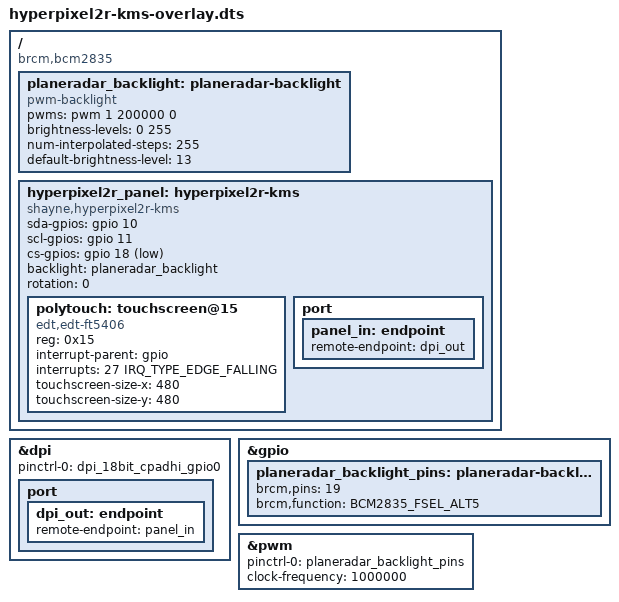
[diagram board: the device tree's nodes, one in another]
// SPDX-License-Identifier: GPL-2.0-only
#include <dt-bindings/gpio/gpio.h>
#include <dt-bindings/interrupt-controller/irq.h>
#include <dt-bindings/pinctrl/bcm2835.h>

/dts-v1/;
/plugin/;

/ {
	compatible = "brcm,bcm2835";

	fragment@0 {
		target-path = "/";
		__overlay__ {
			planeradar_backlight: planeradar-backlight {
				compatible = "pwm-backlight";
				pwms = <&pwm 1 200000 0>;
				brightness-levels = <0 255>;
				num-interpolated-steps = <255>;
				default-brightness-level = <13>;
			};

			hyperpixel2r_panel: hyperpixel2r-kms {
				compatible = "shayne,hyperpixel2r-kms";
				sda-gpios = <&gpio 10 GPIO_ACTIVE_HIGH>;
				scl-gpios = <&gpio 11 GPIO_ACTIVE_HIGH>;
				cs-gpios = <&gpio 18 GPIO_ACTIVE_LOW>;
				backlight = <&planeradar_backlight>;
				rotation = <0>;
				#address-cells = <1>;
				#size-cells = <0>;

				polytouch: touchscreen@15 {
					compatible = "edt,edt-ft5406";
					reg = <0x15>;
					interrupt-parent = <&gpio>;
					interrupts = <27 IRQ_TYPE_EDGE_FALLING>;
					touchscreen-size-x = <480>;
					touchscreen-size-y = <480>;
				};

				port {
					panel_in: endpoint {
						remote-endpoint = <&dpi_out>;
					};
				};
			};
		};
	};

	fragment@1 {
		target = <&dpi>;
		__overlay__ {
			status = "okay";
			pinctrl-names = "default";
			pinctrl-0 = <&dpi_18bit_cpadhi_gpio0>;

			port {
				dpi_out: endpoint {
					remote-endpoint = <&panel_in>;
				};
			};
		};
	};

	fragment@2 {
		target = <&gpio>;
		__overlay__ {
			planeradar_backlight_pins: planeradar-backlight-pins {
				brcm,pins = <19>;
				brcm,function = <BCM2835_FSEL_ALT5>;
			};
		};
	};

	fragment@3 {
		target = <&pwm>;
		__overlay__ {
			status = "okay";
			pinctrl-names = "default";
			pinctrl-0 = <&planeradar_backlight_pins>;
			clock-frequency = <1000000>;
		};
	};

	__overrides__ {
		rotate = <&hyperpixel2r_panel>,"rotation:0";
		touchscreen-inverted-x =
			<&polytouch>,"touchscreen-inverted-x?";
		touchscreen-inverted-y =
			<&polytouch>,"touchscreen-inverted-y?";
		touchscreen-swapped-x-y =
			<&polytouch>,"touchscreen-swapped-x-y?";
	};
};
